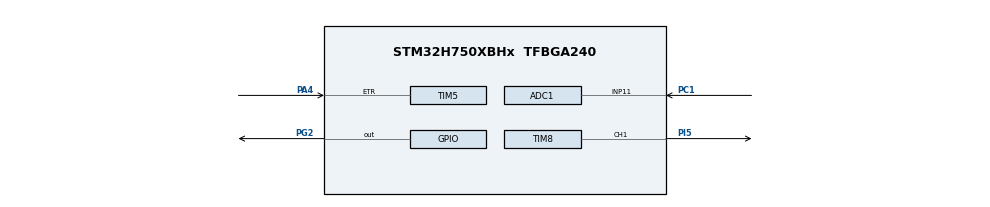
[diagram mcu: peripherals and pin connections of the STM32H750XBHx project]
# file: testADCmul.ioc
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ADC1.Channel-0\#ChannelRegularConversion=ADC_CHANNEL_11
ADC1.NbrOfConversionFlag=1
ADC1.OffsetNumber-0\#ChannelRegularConversion=ADC_OFFSET_NONE
ADC1.OffsetSignedSaturation-0\#ChannelRegularConversion=DISABLE
ADC1.Rank-0\#ChannelRegularConversion=1
ADC1.SamplingTime-0\#ChannelRegularConversion=ADC_SAMPLETIME_1CYCLE_5
ADC1.master=1
ADC2.Channel-0\#ChannelRegularConversion=ADC_CHANNEL_11
ADC2.NbrOfConversionFlag=1
ADC2.OffsetNumber-0\#ChannelRegularConversion=ADC_OFFSET_NONE
ADC2.OffsetSignedSaturation-0\#ChannelRegularConversion=DISABLE
ADC2.Rank-0\#ChannelRegularConversion=1
ADC2.SamplingTime-0\#ChannelRegularConversion=ADC_SAMPLETIME_1CYCLE_5
ADC3.Channel-0\#ChannelRegularConversion=ADC_CHANNEL_11
ADC3.NbrOfConversionFlag=1
ADC3.OffsetNumber-0\#ChannelRegularConversion=ADC_OFFSET_NONE
ADC3.OffsetSignedSaturation-0\#ChannelRegularConversion=DISABLE
ADC3.Rank-0\#ChannelRegularConversion=1
ADC3.SamplingTime-0\#ChannelRegularConversion=ADC_SAMPLETIME_1CYCLE_5
Bdma.ADC3.0.Direction=DMA_PERIPH_TO_MEMORY
Bdma.ADC3.0.EventEnable=DISABLE
Bdma.ADC3.0.Instance=BDMA_Channel0
Bdma.ADC3.0.MemDataAlignment=DMA_MDATAALIGN_HALFWORD
Bdma.ADC3.0.MemInc=DMA_MINC_ENABLE
Bdma.ADC3.0.Mode=DMA_NORMAL
Bdma.ADC3.0.PeriphDataAlignment=DMA_PDATAALIGN_HALFWORD
Bdma.ADC3.0.PeriphInc=DMA_PINC_DISABLE
Bdma.ADC3.0.Polarity=HAL_DMAMUX_REQ_GEN_RISING
Bdma.ADC3.0.Priority=DMA_PRIORITY_LOW
Bdma.ADC3.0.RequestNumber=1
Bdma.ADC3.0.SignalID=NONE
Bdma.ADC3.0.SyncEnable=DISABLE
Bdma.ADC3.0.SyncPolarity=HAL_DMAMUX_SYNC_NO_EVENT
Bdma.ADC3.0.SyncRequestNumber=1
Bdma.ADC3.0.SyncSignalID=NONE
Bdma.Request0=ADC3
Bdma.RequestsNb=1
Mcu.Family=STM32H7
Mcu.Name=STM32H750XBHx
Mcu.Package=TFBGA240
NVIC.BDMA_Channel0_IRQn=true\:0\:0\:false\:false\:true\:false\:true\:true
NVIC.PriorityGroup=NVIC_PRIORITYGROUP_4
NVIC.TIM6_DAC_IRQn=true\:0\:0\:false\:false\:true\:true\:true\:true
NVIC.TIM8_TRG_COM_TIM14_IRQn=true\:0\:0\:false\:false\:true\:true\:true\:true
PA13\ (JTMS/SWDIO).Mode=Serial_Wire
PA13\ (JTMS/SWDIO).Signal=DEBUG_JTMS-SWDIO
PA14\ (JTCK/SWCLK).Mode=Serial_Wire
PA14\ (JTCK/SWCLK).Signal=DEBUG_JTCK-SWCLK
PA4.Signal=S_TIM5_ETR
PC1.Signal=ADCx_INP11
PG2.Signal=GPIO_Output
PH0-OSC_IN\ (PH0).Mode=HSE-External-Oscillator
PH0-OSC_IN\ (PH0).Signal=RCC_OSC_IN
PH1-OSC_OUT\ (PH1).Mode=HSE-External-Oscillator
PH1-OSC_OUT\ (PH1).Signal=RCC_OSC_OUT
PI5.Signal=S_TIM8_CH1
ProjectManager.HeapSize=0x200
ProjectManager.StackSize=0x400
ProjectManager.TargetToolchain=STM32CubeIDE
RCC.ADCCLockSelection=RCC_ADCCLKSOURCE_CLKP
RCC.ADCFreq_Value=64000000
RCC.APB1Freq_Value=120000000
RCC.APB2Freq_Value=120000000
RCC.APB3Freq_Value=120000000
RCC.APB4Freq_Value=120000000
RCC.CortexFreq_Value=480000000
RCC.D1PPRE=RCC_APB3_DIV2
RCC.D2PPRE1=RCC_APB1_DIV2
RCC.D2PPRE2=RCC_APB2_DIV2
RCC.D3PPRE=RCC_APB4_DIV2
RCC.DIVM1=4
RCC.DIVN1=60
RCC.HCLKFreq_Value=240000000
RCC.HPRE=RCC_HCLK_DIV2
RCC.PLL2FRACN=0
RCC.PLL3FRACN=0
RCC.PLLFRACN=0
RCC.SYSCLKFreq_VALUE=480000000
RCC.SYSCLKSource=RCC_SYSCLKSOURCE_PLLCLK
RCC.USBFreq_Value=480000000
SH.ADCx_INP11.0=ADC1_INP11,IN11-Single-Ended
SH.ADCx_INP11.1=ADC2_INP11,IN11-Single-Ended
SH.ADCx_INP11.2=ADC3_INP11,IN11-Single-Ended
SH.S_TIM5_ETR.0=TIM5_ETR,ClockSourceETR_Mode2
SH.S_TIM8_CH1.0=TIM8_CH1,PWM Generation1 CH1
TIM5.AutoReloadPreload=TIM_AUTORELOAD_PRELOAD_ENABLE
TIM6.Period=4800-1
TIM6.Prescaler=50000-1
TIM8.Channel-PWM\ Generation1\ CH1=TIM_CHANNEL_1
TIM8.Period=4800-1
TIM8.Prescaler=50000-1
TIM8.Pulse-PWM\ Generation1\ CH1=2400-1
VP_TIM6_VS_ClockSourceINT.Mode=Enable_Timer
VP_TIM8_VS_ClockSourceINT.Mode=Internal
VP_VREFBUF_V_VREFBUF.Mode=ExternalMode
board=custom

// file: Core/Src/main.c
/* USER CODE BEGIN Header */
/**
  ******************************************************************************
  * @file           : main.c
  * @brief          : Main program body
  ******************************************************************************
  * @attention
  *
  * Copyright (c) 2024 STMicroelectronics.
  * All rights reserved.
  *
  * This software is licensed under terms that can be found in the LICENSE file
  * in the root directory of this software component.
  * If no LICENSE file comes with this software, it is provided AS-IS.
  *
  ******************************************************************************
  */
/* USER CODE END Header */
#include "main.h"

/* USER CODE BEGIN PD */

uint32_t USER_CounterTicks=0;
/* USER CODE END PD */

ADC_HandleTypeDef hadc1;
ADC_HandleTypeDef hadc2;
ADC_HandleTypeDef hadc3;
DMA_HandleTypeDef hdma_adc3;

TIM_HandleTypeDef htim5;
TIM_HandleTypeDef htim6;
TIM_HandleTypeDef htim8;

void SystemClock_Config(void);
void PeriphCommonClock_Config(void);
static void MX_GPIO_Init(void);
static void MX_BDMA_Init(void);
static void MX_TIM8_Init(void);
static void MX_ADC1_Init(void);
static void MX_ADC2_Init(void);
static void MX_ADC3_Init(void);
static void MX_TIM5_Init(void);
static void MX_TIM6_Init(void);

int main(void)
{

  /* MCU Configuration--------------------------------------------------------*/

  /* Reset of all peripherals, Initializes the Flash interface and the Systick. */
  HAL_Init();

  /* Configure the system clock */
  SystemClock_Config();

/* Configure the peripherals common clocks */
  PeriphCommonClock_Config();

  /* Initialize all configured peripherals */
  MX_GPIO_Init();
  MX_BDMA_Init();
  MX_TIM8_Init();
  MX_ADC1_Init();
  MX_ADC2_Init();
  MX_ADC3_Init();
  MX_TIM5_Init();
  MX_TIM6_Init();
  /* USER CODE BEGIN 2 */

//HAL_Delay(10);
  HAL_TIM_Base_Start_IT(&htim6);
  HAL_TIM_Base_Start(&htim5);

  HAL_TIM_PWM_Start(&htim8, TIM_CHANNEL_1);
  /* USER CODE END 2 */

  /* Infinite loop */
  while (1)
  {

  }
}

void SystemClock_Config(void)
{
  RCC_OscInitTypeDef RCC_OscInitStruct = {0};
  RCC_ClkInitTypeDef RCC_ClkInitStruct = {0};

  /** Supply configuration update enable
  */
  HAL_PWREx_ConfigSupply(PWR_LDO_SUPPLY);

  /** Configure the main internal regulator output voltage
  */
  __HAL_PWR_VOLTAGESCALING_CONFIG(PWR_REGULATOR_VOLTAGE_SCALE1);

  while(!__HAL_PWR_GET_FLAG(PWR_FLAG_VOSRDY)) {}

  __HAL_RCC_SYSCFG_CLK_ENABLE();
  __HAL_PWR_VOLTAGESCALING_CONFIG(PWR_REGULATOR_VOLTAGE_SCALE0);

  while(!__HAL_PWR_GET_FLAG(PWR_FLAG_VOSRDY)) {}

  /** Initializes the RCC Oscillators according to the specified parameters
  * in the RCC_OscInitTypeDef structure.
  */
  RCC_OscInitStruct.OscillatorType = RCC_OSCILLATORTYPE_HSI;
  RCC_OscInitStruct.HSIState = RCC_HSI_DIV1;
  RCC_OscInitStruct.HSICalibrationValue = RCC_HSICALIBRATION_DEFAULT;
  RCC_OscInitStruct.PLL.PLLState = RCC_PLL_ON;
  RCC_OscInitStruct.PLL.PLLSource = RCC_PLLSOURCE_HSI;
  RCC_OscInitStruct.PLL.PLLM = 4;
  RCC_OscInitStruct.PLL.PLLN = 60;
  RCC_OscInitStruct.PLL.PLLP = 2;
  RCC_OscInitStruct.PLL.PLLQ = 2;
  RCC_OscInitStruct.PLL.PLLR = 2;
  RCC_OscInitStruct.PLL.PLLRGE = RCC_PLL1VCIRANGE_3;
  RCC_OscInitStruct.PLL.PLLVCOSEL = RCC_PLL1VCOWIDE;
  RCC_OscInitStruct.PLL.PLLFRACN = 0;
  if (HAL_RCC_OscConfig(&RCC_OscInitStruct) != HAL_OK)
  {
    Error_Handler();
  }

  /** Initializes the CPU, AHB and APB buses clocks
  */
  RCC_ClkInitStruct.ClockType = RCC_CLOCKTYPE_HCLK|RCC_CLOCKTYPE_SYSCLK
                              |RCC_CLOCKTYPE_PCLK1|RCC_CLOCKTYPE_PCLK2
                              |RCC_CLOCKTYPE_D3PCLK1|RCC_CLOCKTYPE_D1PCLK1;
  RCC_ClkInitStruct.SYSCLKSource = RCC_SYSCLKSOURCE_PLLCLK;
  RCC_ClkInitStruct.SYSCLKDivider = RCC_SYSCLK_DIV1;
  RCC_ClkInitStruct.AHBCLKDivider = RCC_HCLK_DIV2;
  RCC_ClkInitStruct.APB3CLKDivider = RCC_APB3_DIV2;
  RCC_ClkInitStruct.APB1CLKDivider = RCC_APB1_DIV2;
  RCC_ClkInitStruct.APB2CLKDivider = RCC_APB2_DIV2;
  RCC_ClkInitStruct.APB4CLKDivider = RCC_APB4_DIV2;

  if (HAL_RCC_ClockConfig(&RCC_ClkInitStruct, FLASH_LATENCY_4) != HAL_OK)
  {
    Error_Handler();
  }
}

void PeriphCommonClock_Config(void)
{
  RCC_PeriphCLKInitTypeDef PeriphClkInitStruct = {0};

  /** Initializes the peripherals clock
  */
  PeriphClkInitStruct.PeriphClockSelection = RCC_PERIPHCLK_CKPER;
  PeriphClkInitStruct.CkperClockSelection = RCC_CLKPSOURCE_HSI;
  if (HAL_RCCEx_PeriphCLKConfig(&PeriphClkInitStruct) != HAL_OK)
  {
    Error_Handler();
  }
}

static void MX_ADC1_Init(void)
{

  ADC_MultiModeTypeDef multimode = {0};
  ADC_ChannelConfTypeDef sConfig = {0};

  /** Common config
  */
  hadc1.Instance = ADC1;
  hadc1.Init.ClockPrescaler = ADC_CLOCK_ASYNC_DIV1;
  hadc1.Init.Resolution = ADC_RESOLUTION_16B;
  hadc1.Init.ScanConvMode = ADC_SCAN_DISABLE;
  hadc1.Init.EOCSelection = ADC_EOC_SINGLE_CONV;
  hadc1.Init.LowPowerAutoWait = DISABLE;
  hadc1.Init.ContinuousConvMode = DISABLE;
  hadc1.Init.NbrOfConversion = 1;
  hadc1.Init.DiscontinuousConvMode = DISABLE;
  hadc1.Init.ExternalTrigConv = ADC_SOFTWARE_START;
  hadc1.Init.ExternalTrigConvEdge = ADC_EXTERNALTRIGCONVEDGE_NONE;
  hadc1.Init.ConversionDataManagement = ADC_CONVERSIONDATA_DR;
  hadc1.Init.Overrun = ADC_OVR_DATA_PRESERVED;
  hadc1.Init.LeftBitShift = ADC_LEFTBITSHIFT_NONE;
  hadc1.Init.OversamplingMode = DISABLE;
  if (HAL_ADC_Init(&hadc1) != HAL_OK)
  {
    Error_Handler();
  }

  /** Configure the ADC multi-mode
  */
  multimode.Mode = ADC_MODE_INDEPENDENT;
  if (HAL_ADCEx_MultiModeConfigChannel(&hadc1, &multimode) != HAL_OK)
  {
    Error_Handler();
  }

  /** Configure Regular Channel
  */
  sConfig.Channel = ADC_CHANNEL_11;
  sConfig.Rank = ADC_REGULAR_RANK_1;
  sConfig.SamplingTime = ADC_SAMPLETIME_1CYCLE_5;
  sConfig.SingleDiff = ADC_SINGLE_ENDED;
  sConfig.OffsetNumber = ADC_OFFSET_NONE;
  sConfig.Offset = 0;
  sConfig.OffsetSignedSaturation = DISABLE;
  if (HAL_ADC_ConfigChannel(&hadc1, &sConfig) != HAL_OK)
  {
    Error_Handler();
  }

}

static void MX_ADC2_Init(void)
{

  ADC_ChannelConfTypeDef sConfig = {0};

  /** Common config
  */
  hadc2.Instance = ADC2;
  hadc2.Init.ClockPrescaler = ADC_CLOCK_ASYNC_DIV1;
  hadc2.Init.Resolution = ADC_RESOLUTION_16B;
  hadc2.Init.ScanConvMode = ADC_SCAN_DISABLE;
  hadc2.Init.EOCSelection = ADC_EOC_SINGLE_CONV;
  hadc2.Init.LowPowerAutoWait = DISABLE;
  hadc2.Init.ContinuousConvMode = DISABLE;
  hadc2.Init.NbrOfConversion = 1;
  hadc2.Init.DiscontinuousConvMode = DISABLE;
  hadc2.Init.ExternalTrigConv = ADC_SOFTWARE_START;
  hadc2.Init.ExternalTrigConvEdge = ADC_EXTERNALTRIGCONVEDGE_NONE;
  hadc2.Init.ConversionDataManagement = ADC_CONVERSIONDATA_DR;
  hadc2.Init.Overrun = ADC_OVR_DATA_PRESERVED;
  hadc2.Init.LeftBitShift = ADC_LEFTBITSHIFT_NONE;
  hadc2.Init.OversamplingMode = DISABLE;
  if (HAL_ADC_Init(&hadc2) != HAL_OK)
  {
    Error_Handler();
  }

  /** Configure Regular Channel
  */
  sConfig.Channel = ADC_CHANNEL_11;
  sConfig.Rank = ADC_REGULAR_RANK_1;
  sConfig.SamplingTime = ADC_SAMPLETIME_1CYCLE_5;
  sConfig.SingleDiff = ADC_SINGLE_ENDED;
  sConfig.OffsetNumber = ADC_OFFSET_NONE;
  sConfig.Offset = 0;
  sConfig.OffsetSignedSaturation = DISABLE;
  if (HAL_ADC_ConfigChannel(&hadc2, &sConfig) != HAL_OK)
  {
    Error_Handler();
  }

}

static void MX_ADC3_Init(void)
{

  ADC_ChannelConfTypeDef sConfig = {0};

  /** Common config
  */
  hadc3.Instance = ADC3;
  hadc3.Init.Resolution = ADC_RESOLUTION_16B;
  hadc3.Init.ScanConvMode = ADC_SCAN_DISABLE;
  hadc3.Init.EOCSelection = ADC_EOC_SINGLE_CONV;
  hadc3.Init.LowPowerAutoWait = DISABLE;
  hadc3.Init.ContinuousConvMode = DISABLE;
  hadc3.Init.NbrOfConversion = 1;
  hadc3.Init.DiscontinuousConvMode = DISABLE;
  hadc3.Init.ExternalTrigConv = ADC_SOFTWARE_START;
  hadc3.Init.ExternalTrigConvEdge = ADC_EXTERNALTRIGCONVEDGE_NONE;
  hadc3.Init.ConversionDataManagement = ADC_CONVERSIONDATA_DR;
  hadc3.Init.Overrun = ADC_OVR_DATA_PRESERVED;
  hadc3.Init.LeftBitShift = ADC_LEFTBITSHIFT_NONE;
  hadc3.Init.OversamplingMode = DISABLE;
  if (HAL_ADC_Init(&hadc3) != HAL_OK)
  {
    Error_Handler();
  }

  /** Configure Regular Channel
  */
  sConfig.Channel = ADC_CHANNEL_11;
  sConfig.Rank = ADC_REGULAR_RANK_1;
  sConfig.SamplingTime = ADC_SAMPLETIME_1CYCLE_5;
  sConfig.SingleDiff = ADC_SINGLE_ENDED;
  sConfig.OffsetNumber = ADC_OFFSET_NONE;
  sConfig.Offset = 0;
  sConfig.OffsetSignedSaturation = DISABLE;
  if (HAL_ADC_ConfigChannel(&hadc3, &sConfig) != HAL_OK)
  {
    Error_Handler();
  }

}

static void MX_TIM5_Init(void)
{

  TIM_ClockConfigTypeDef sClockSourceConfig = {0};
  TIM_MasterConfigTypeDef sMasterConfig = {0};

  htim5.Instance = TIM5;
  htim5.Init.Prescaler = 0;
  htim5.Init.CounterMode = TIM_COUNTERMODE_UP;
  htim5.Init.Period = 4294967295;
  htim5.Init.ClockDivision = TIM_CLOCKDIVISION_DIV1;
  htim5.Init.AutoReloadPreload = TIM_AUTORELOAD_PRELOAD_ENABLE;
  if (HAL_TIM_Base_Init(&htim5) != HAL_OK)
  {
    Error_Handler();
  }
  sClockSourceConfig.ClockSource = TIM_CLOCKSOURCE_ETRMODE2;
  sClockSourceConfig.ClockPolarity = TIM_CLOCKPOLARITY_NONINVERTED;
  sClockSourceConfig.ClockPrescaler = TIM_CLOCKPRESCALER_DIV1;
  sClockSourceConfig.ClockFilter = 0;
  if (HAL_TIM_ConfigClockSource(&htim5, &sClockSourceConfig) != HAL_OK)
  {
    Error_Handler();
  }
  sMasterConfig.MasterOutputTrigger = TIM_TRGO_RESET;
  sMasterConfig.MasterSlaveMode = TIM_MASTERSLAVEMODE_DISABLE;
  if (HAL_TIMEx_MasterConfigSynchronization(&htim5, &sMasterConfig) != HAL_OK)
  {
    Error_Handler();
  }

}

static void MX_TIM6_Init(void)
{

  TIM_MasterConfigTypeDef sMasterConfig = {0};

  htim6.Instance = TIM6;
  htim6.Init.Prescaler = 50000-1;
  htim6.Init.CounterMode = TIM_COUNTERMODE_UP;
  htim6.Init.Period = 4800-1;
  htim6.Init.AutoReloadPreload = TIM_AUTORELOAD_PRELOAD_DISABLE;
  if (HAL_TIM_Base_Init(&htim6) != HAL_OK)
  {
    Error_Handler();
  }
  sMasterConfig.MasterOutputTrigger = TIM_TRGO_RESET;
  sMasterConfig.MasterSlaveMode = TIM_MASTERSLAVEMODE_DISABLE;
  if (HAL_TIMEx_MasterConfigSynchronization(&htim6, &sMasterConfig) != HAL_OK)
  {
    Error_Handler();
  }

}

static void MX_TIM8_Init(void)
{

  TIM_ClockConfigTypeDef sClockSourceConfig = {0};
  TIM_MasterConfigTypeDef sMasterConfig = {0};
  TIM_OC_InitTypeDef sConfigOC = {0};
  TIM_BreakDeadTimeConfigTypeDef sBreakDeadTimeConfig = {0};

  htim8.Instance = TIM8;
  htim8.Init.Prescaler = 50000-1;
  htim8.Init.CounterMode = TIM_COUNTERMODE_UP;
  htim8.Init.Period = 4800-1;
  htim8.Init.ClockDivision = TIM_CLOCKDIVISION_DIV1;
  htim8.Init.RepetitionCounter = 0;
  htim8.Init.AutoReloadPreload = TIM_AUTORELOAD_PRELOAD_DISABLE;
  if (HAL_TIM_Base_Init(&htim8) != HAL_OK)
  {
    Error_Handler();
  }
  sClockSourceConfig.ClockSource = TIM_CLOCKSOURCE_INTERNAL;
  if (HAL_TIM_ConfigClockSource(&htim8, &sClockSourceConfig) != HAL_OK)
  {
    Error_Handler();
  }
  if (HAL_TIM_PWM_Init(&htim8) != HAL_OK)
  {
    Error_Handler();
  }
  sMasterConfig.MasterOutputTrigger = TIM_TRGO_RESET;
  sMasterConfig.MasterOutputTrigger2 = TIM_TRGO2_RESET;
  sMasterConfig.MasterSlaveMode = TIM_MASTERSLAVEMODE_DISABLE;
  if (HAL_TIMEx_MasterConfigSynchronization(&htim8, &sMasterConfig) != HAL_OK)
  {
    Error_Handler();
  }
  sConfigOC.OCMode = TIM_OCMODE_PWM1;
  sConfigOC.Pulse = 2400-1;
  sConfigOC.OCPolarity = TIM_OCPOLARITY_HIGH;
  sConfigOC.OCNPolarity = TIM_OCNPOLARITY_HIGH;
  sConfigOC.OCFastMode = TIM_OCFAST_DISABLE;
  sConfigOC.OCIdleState = TIM_OCIDLESTATE_RESET;
  sConfigOC.OCNIdleState = TIM_OCNIDLESTATE_RESET;
  if (HAL_TIM_PWM_ConfigChannel(&htim8, &sConfigOC, TIM_CHANNEL_1) != HAL_OK)
  {
    Error_Handler();
  }
  sBreakDeadTimeConfig.OffStateRunMode = TIM_OSSR_DISABLE;
  sBreakDeadTimeConfig.OffStateIDLEMode = TIM_OSSI_DISABLE;
  sBreakDeadTimeConfig.LockLevel = TIM_LOCKLEVEL_OFF;
  sBreakDeadTimeConfig.DeadTime = 0;
  sBreakDeadTimeConfig.BreakState = TIM_BREAK_DISABLE;
  sBreakDeadTimeConfig.BreakPolarity = TIM_BREAKPOLARITY_HIGH;
  sBreakDeadTimeConfig.BreakFilter = 0;
  sBreakDeadTimeConfig.Break2State = TIM_BREAK2_DISABLE;
  sBreakDeadTimeConfig.Break2Polarity = TIM_BREAK2POLARITY_HIGH;
  sBreakDeadTimeConfig.Break2Filter = 0;
  sBreakDeadTimeConfig.AutomaticOutput = TIM_AUTOMATICOUTPUT_DISABLE;
  if (HAL_TIMEx_ConfigBreakDeadTime(&htim8, &sBreakDeadTimeConfig) != HAL_OK)
  {
    Error_Handler();
  }
  HAL_TIM_MspPostInit(&htim8);

}

static void MX_BDMA_Init(void)
{

  /* DMA controller clock enable */
  __HAL_RCC_BDMA_CLK_ENABLE();

  /* DMA interrupt init */
  /* BDMA_Channel0_IRQn interrupt configuration */
  HAL_NVIC_SetPriority(BDMA_Channel0_IRQn, 0, 0);
  HAL_NVIC_EnableIRQ(BDMA_Channel0_IRQn);

}

static void MX_GPIO_Init(void)
{
  GPIO_InitTypeDef GPIO_InitStruct = {0};

  /* GPIO Ports Clock Enable */
  __HAL_RCC_GPIOI_CLK_ENABLE();
  __HAL_RCC_GPIOA_CLK_ENABLE();
  __HAL_RCC_GPIOG_CLK_ENABLE();
  __HAL_RCC_GPIOH_CLK_ENABLE();
  __HAL_RCC_GPIOC_CLK_ENABLE();

  /*Configure GPIO pin Output Level */
  HAL_GPIO_WritePin(GPIOG, GPIO_PIN_2, GPIO_PIN_RESET);

  /*Configure GPIO pin : PG2 */
  GPIO_InitStruct.Pin = GPIO_PIN_2;
  GPIO_InitStruct.Mode = GPIO_MODE_OUTPUT_PP;
  GPIO_InitStruct.Pull = GPIO_NOPULL;
  GPIO_InitStruct.Speed = GPIO_SPEED_FREQ_LOW;
  HAL_GPIO_Init(GPIOG, &GPIO_InitStruct);

}

void Error_Handler(void)
{
  __disable_irq();
  while (1)
  {
  }
}
